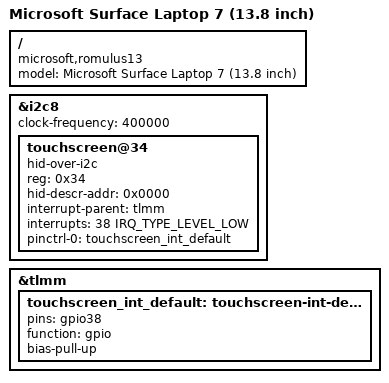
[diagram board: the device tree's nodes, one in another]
// SPDX-License-Identifier: BSD-3-Clause
/*
 * Copyright (c) 2024 Qualcomm Innovation Center, Inc. All rights reserved.
 */

/dts-v1/;

#include "x1e80100-microsoft-romulus.dtsi"

/ {
	model = "Microsoft Surface Laptop 7 (13.8 inch)";
	compatible = "microsoft,romulus13", "qcom,x1e80100";
};

&i2c8 {
	clock-frequency = <400000>;

	status = "okay";

	touchscreen@34 {
		compatible = "hid-over-i2c";
		reg = <0x34>;
		hid-descr-addr = <0x0000>;

		interrupt-parent = <&tlmm>;
		interrupts = <38 IRQ_TYPE_LEVEL_LOW>;

		pinctrl-0 = <&touchscreen_int_default>;
		pinctrl-names = "default";
	};
};

&tlmm {
	touchscreen_int_default: touchscreen-int-default-state {
		pins = "gpio38";
		function = "gpio";
		bias-pull-up;
	};
};
